# RA4M1 register map
Vendor: Renesas Electronics Corporation; Series: RA4; File version: 1.2
CPU: CM4 r0p1, little endian, MPU, FPU, VTOR, 4 interrupt priority bits
Registers are 8-bit, read-write, reset 0x0 unless marked. A register's access mark holds for its fields unless they carry their own. Offsets are from the block's base; [hi:lo] are bit positions; {n}, {i} and the like mark numbered series.

## GPT162 (part 1 of 2) — General PWM Timer 2 (16-bit)
Base 0x40078200
Same registers: GPT163 0x40078300, GPT164 0x40078400, GPT165 0x40078500, GPT166 0x40078600, GPT167 0x40078700
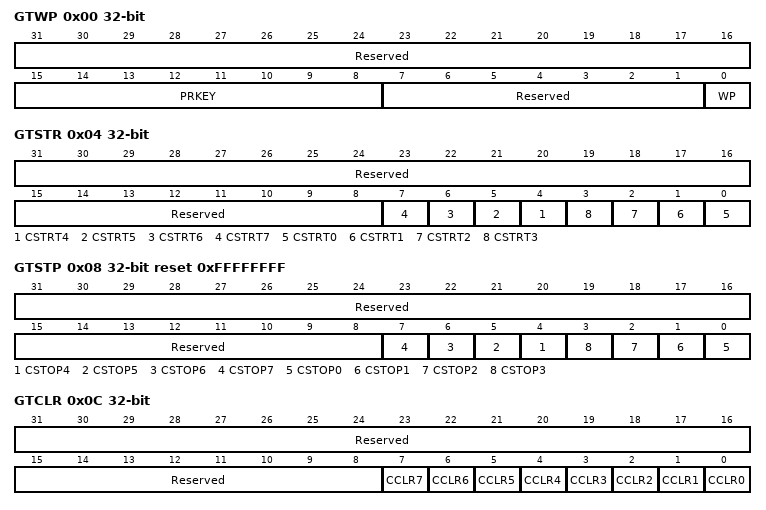
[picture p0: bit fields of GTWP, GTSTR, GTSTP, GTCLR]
0x00 GTWP 32-bit — General PWM Timer Write-Protection Register
  [31:16] Reserved — These bits are read as 0000000000000000. The write value should be 0000000000000000.
  [15:8] PRKEY wo — GTWP Key Code
    165=Written to these bits, the WP bits write is permitted; other=others (The WP bits write is not permitted.)
  [7:1] Reserved — These bits are read as 0000000. The write value should be 0000000.
  [0] WP — Register Write Disable
    0=Write to the register is enabled; 1=Write to the register is disabled
0x04 GTSTR 32-bit — General PWM Timer Software Start Register
  [31:8] Reserved — These bits are read as 000000000000000000000000. The write value should be 000000000000000000000000.
  [n] CSTRT{n} (n=4..7) — Channel {n} GTCNT Count Start Read data shows each channel's counter status (GTCR.CST bit). 0 means counter stop. 1 means counter running.
    0=No effect (write) / counter stop (read); 1=GPT{n+160}.GTCNT counter starts (write) / Counter running (read)
  [n] CSTRT{n} (n=0..3) — Channel {n} GTCNT Count Start Read data shows each channel's counter status (GTCR.CST bit). 0 means counter stop. 1 means counter running.
    0=No effect (write) / counter stop (read); 1=GPT{n+320}.GTCNT counter starts (write) / Counter running (read)
0x08 GTSTP 32-bit reset 0xFFFFFFFF — General PWM Timer Software Stop Register
  [31:8] Reserved — These bits are read as 111111111111111111111111. The write value should be 111111111111111111111111.
  [n] CSTOP{n} (n=4..7) — Channel {n} GTCNT Count Stop Read data shows each channel's counter status (GTCR.CST bit). 0 means counter runnning. 1 means counter stop.
    0=No effect (write) / counter running (read); 1=GPT{n+160}.GTCNT counter stops (write) / Counter stop (read)
  [n] CSTOP{n} (n=0..3) — Channel {n} GTCNT Count Stop Read data shows each channel's counter status (GTCR.CST bit). 0 means counter runnning. 1 means counter stop.
    0=No effect (write) / counter running (read); 1=GPT{n+320}.GTCNT counter stops (write) / Counter stop (read)
0x0C GTCLR 32-bit wo — General PWM Timer Software Clear Register
  [31:8] Reserved — The write value should be 000000000000000000000000.
  [n] CCLR{n} (n=4..7) — Channel {n} GTCNT Count Clear
    0=No effect; 1=GPT{n+160}.GTCNT counter clears
  [n] CCLR{n} (n=0..3) — Channel {n} GTCNT Count Clear
    0=No effect; 1=GPT{n+320}.GTCNT counter clears
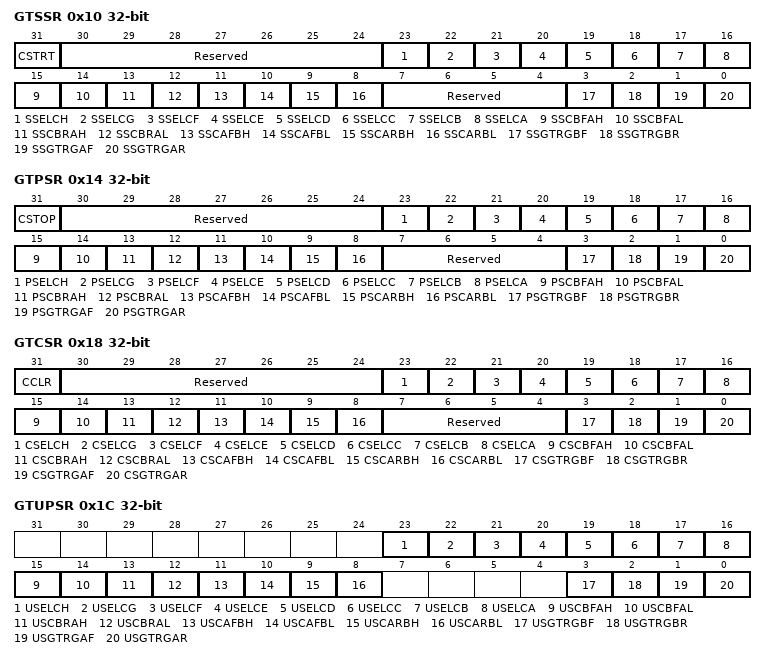
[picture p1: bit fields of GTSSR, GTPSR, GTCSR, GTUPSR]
0x10 GTSSR 32-bit — General PWM Timer Start Source Select Register
  [31] CSTRT — Software Source Counter Start Enable
    0=Counter start is disable by the GTSTR register; 1=Counter start is enable by the GTSTR register
  [30:24] Reserved — These bits are read as 0000000. The write value should be 0000000.
  [23] SSELCH — ELC_GPTH Event Source Counter Start Enable
    0=Counter start is disable at the ELC_GPTH input; 1=Counter start is enable at the ELC_GPTH input
  [22] SSELCG — ELC_GPTG Event Source Counter Start Enable
    0=Counter start is disable at the ELC_GPTG input; 1=Counter start is enable at the ELC_GPTG input
  [21] SSELCF — ELC_GPTF Event Source Counter Start Enable
    0=Counter start is disable at the ELC_GPTF input; 1=Counter start is enable at the ELC_GPTF input
  [20] SSELCE — ELC_GPTE Event Source Counter Start Enable
    0=Counter start is disable at the ELC_GPTE input; 1=Counter start is enable at the ELC_GPTE input
  [19] SSELCD — ELC_GPTD Event Source Counter Start Enable
    0=Counter start is disable at the ELC_GPTD input; 1=Counter start is enable at the ELC_GPTD input
  [18] SSELCC — ELC_GPTC Event Source Counter Start Enable
    0=Counter start is disable at the ELC_GPTC input; 1=Counter start is enable at the ELC_GPTC input
  [17] SSELCB — ELC_GPTB Event Source Counter Start Enable
    0=Counter start is disable at the ELC_GPTB input; 1=Counter start is enable at the ELC_GPTB input
  [16] SSELCA — ELC_GPTA Event Source Counter Start Enable
    0=Counter start is disable at the ELC_GPTA input; 1=Counter start is enable at the ELC_GPTA input
  [15] SSCBFAH — GTIOCB Pin Falling Input during GTIOCA Value High Source Counter Start Enable
    0=Counter start is disable at the falling edge of GTIOCB input when GTIOCA input is 1; 1=Counter start is enable at the falling edge of GTIOCB input when GTIOCA input is 1
  [14] SSCBFAL — GTIOCB Pin Falling Input during GTIOCA Value Low Source Counter Start Enable
    0=Counter start is disable at the falling edge of GTIOCB input when GTIOCA input is 0; 1=Counter start is enable at the falling edge of GTIOCB input when GTIOCA input is 0
  [13] SSCBRAH — GTIOCB Pin Rising Input during GTIOCA Value High Source Counter Start Enable
    0=Counter start is disable at the rising edge of GTIOCB input when GTIOCA input is 1; 1=Counter start is enable at the rising edge of GTIOCB input when GTIOCA input is 1
  [12] SSCBRAL — GTIOCB Pin Rising Input during GTIOCA Value Low Source Counter Start Enable
    0=Counter start is disable at the rising edge of GTIOCB input when GTIOCA input is 0; 1=Counter start is enable at the rising edge of GTIOCB input when GTIOCA input is 0
  [11] SSCAFBH — GTIOCA Pin Falling Input during GTIOCB Value High Source Counter Start Enable
    0=Counter start is disable at the falling edge of GTIOCA input when GTIOCB input is 1; 1=Counter start is enable at the falling edge of GTIOCA input when GTIOCB input is 1
  [10] SSCAFBL — GTIOCA Pin Falling Input during GTIOCB Value Low Source Counter Start Enable
    0=Counter start is disable at the falling edge of GTIOCA input when GTIOCB input is 0; 1=Counter start is enable at the falling edge of GTIOCA input when GTIOCB input is 0
  [9] SSCARBH — GTIOCA Pin Rising Input during GTIOCB Value High Source Counter Start Enable
    0=Counter start is disable at the rising edge of GTIOCA input when GTIOCB input is 1; 1=Counter start is enable at the rising edge of GTIOCA input when GTIOCB input is 1
  [8] SSCARBL — GTIOCA Pin Rising Input during GTIOCB Value Low Source Counter Start Enable
    0=Counter start is disable at the rising edge of GTIOCA input when GTIOCB input is 0; 1=Counter start is enable at the rising edge of GTIOCA input when GTIOCB input is 0
  [7:4] Reserved — These bits are read as 0000. The write value should be 0000.
  [3] SSGTRGBF — GTETRGB Pin Falling Input Source Counter Start Enable
    0=Counter start is disable at the falling edge of GTETRGB input; 1=Counter start is enable at the falling edge of GTETRGB input
  [2] SSGTRGBR — GTETRGB Pin Rising Input Source Counter Start Enable
    0=Counter start is disable at the rising edge of GTETRGB input; 1=Counter start is enable at the rising edge of GTETRGB input
  [1] SSGTRGAF — GTETRGA Pin Falling Input Source Counter Start Enable
    0=Counter start is disable at the falling edge of GTETRGA input; 1=Counter start is enable at the falling edge of GTETRGA input
  [0] SSGTRGAR — GTETRGA Pin Rising Input Source Counter Start Enable
    0=Counter start is disable at the rising edge of GTETRGA input; 1=Counter start is enable at the rising edge of GTETRGA input
0x14 GTPSR 32-bit — General PWM Timer Stop Source Select Register
  [31] CSTOP — Software Source Counter Stop Enable
    0=Counter stop is disable by the GTSTP register; 1=Counter stop is enable by the GTSTP register
  [30:24] Reserved — These bits are read as 0000000. The write value should be 0000000.
  [23] PSELCH — ELC_GPTH Event Source Counter Stop Enable
    0=Counter stop is disable at the ELC_GPTH input; 1=Counter stop is enable at the ELC_GPTH input
  [22] PSELCG — ELC_GPTG Event Source Counter Stop Enable
    0=Counter stop is disable at the ELC_GPTG input; 1=Counter stop is enable at the ELC_GPTG input
  [21] PSELCF — ELC_GPTF Event Source Counter Stop Enable
    0=Counter stop is disable at the ELC_GPTF input; 1=Counter stop is enable at the ELC_GPTF input
  [20] PSELCE — ELC_GPTE Event Source Counter Stop Enable
    0=Counter stop is disable at the ELC_GPTE input; 1=Counter stop is enable at the ELC_GPTE input
  [19] PSELCD — ELC_GPTD Event Source Counter Stop Enable
    0=Counter stop is disable at the ELC_GPTD input; 1=Counter stop is enable at the ELC_GPTD input
  [18] PSELCC — ELC_GPTC Event Source Counter Stop Enable
    0=Counter stop is disable at the ELC_GPTC input; 1=Counter stop is enable at the ELC_GPTC input
  [17] PSELCB — ELC_GPTB Event Source Counter Stop Enable
    0=Counter stop is disable at the ELC_GPTB input; 1=Counter stop is enable at the ELC_GPTB input
  [16] PSELCA — ELC_GPTA Event Source Counter Stop Enable
    0=Counter stop is disable at the ELC_GPTA input; 1=Counter stop is enable at the ELC_GPTA input
  [15] PSCBFAH — GTIOCB Pin Falling Input during GTIOCA Value High Source Counter Stop Enable
    0=Counter stop is disable at the falling edge of GTIOCB input when GTIOCA input is 1; 1=Counter stop is enable at the falling edge of GTIOCB input when GTIOCA input is 1
  [14] PSCBFAL — GTIOCB Pin Falling Input during GTIOCA Value Low Source Counter Stop Enable
    0=Counter stop is disable at the falling edge of GTIOCB input when GTIOCA input is 0; 1=Counter stop is enable at the falling edge of GTIOCB input when GTIOCA input is 0
  [13] PSCBRAH — GTIOCB Pin Rising Input during GTIOCA Value High Source Counter Stop Enable
    0=Counter stop is disable at the rising edge of GTIOCB input when GTIOCA input is 1; 1=Counter stop is enable at the rising edge of GTIOCB input when GTIOCA input is 1
  [12] PSCBRAL — GTIOCB Pin Rising Input during GTIOCA Value Low Source Counter Stop Enable
    0=Counter stop is disable at the rising edge of GTIOCB input when GTIOCA input is 0; 1=Counter stop is enable at the rising edge of GTIOCB input when GTIOCA input is 0
  [11] PSCAFBH — GTIOCA Pin Falling Input during GTIOCB Value High Source Counter Stop Enable
    0=Counter stop is disable at the falling edge of GTIOCA input when GTIOCB input is 1; 1=Counter stop is enable at the falling edge of GTIOCA input when GTIOCB input is 1
  [10] PSCAFBL — GTIOCA Pin Falling Input during GTIOCB Value Low Source Counter Stop Enable
    0=Counter stop is disable at the falling edge of GTIOCA input when GTIOCB input is 0; 1=Counter stop is enable at the falling edge of GTIOCA input when GTIOCB input is 0
  [9] PSCARBH — GTIOCA Pin Rising Input during GTIOCB Value High Source Counter Stop Enable
    0=Counter stop is disable at the rising edge of GTIOCA input when GTIOCB input is 1; 1=Counter stop is enable at the rising edge of GTIOCA input when GTIOCB input is 1
  [8] PSCARBL — GTIOCA Pin Rising Input during GTIOCB Value Low Source Counter Stop Enable
    0=Counter stop is disable at the rising edge of GTIOCA input when GTIOCB input is 0; 1=Counter stop is enable at the rising edge of GTIOCA input when GTIOCB input is 0
  [7:4] Reserved — These bits are read as 0000. The write value should be 0000.
  [3] PSGTRGBF — GTETRGB Pin Falling Input Source Counter Stop Enable
    0=Counter stop is disable at the falling edge of GTETRGB input; 1=Counter stop is enable at the falling edge of GTETRGB input
  [2] PSGTRGBR — GTETRGB Pin Rising Input Source Counter Stop Enable
    0=Counter stop is disable at the rising edge of GTETRGB input; 1=Counter stop is enable at the rising edge of GTETRGB input
  [1] PSGTRGAF — GTETRGA Pin Falling Input Source Counter Stop Enable
    0=Counter stop is disable at the falling edge of GTETRGA input; 1=Counter stop is enable at the falling edge of GTETRGA input
  [0] PSGTRGAR — GTETRGA Pin Rising Input Source Counter Stop Enable
    0=Counter stop is disable at the rising edge of GTETRGA input; 1=Counter stop is enable at the rising edge of GTETRGA input
0x18 GTCSR 32-bit — General PWM Timer Clear Source Select Register
  [31] CCLR — Software Source Counter Clear Enable
    0=Counter clear is disable by the GTCLR register; 1=Counter clear is enable by the GTCLR register
  [30:24] Reserved — These bits are read as 0000000. The write value should be 0000000.
  [23] CSELCH — ELC_GPTH Event Source Counter Clear Enable
    0=Counter clear is disable at the ELC_GPTH input; 1=Counter clear is enable at the ELC_GPTH input
  [22] CSELCG — ELC_GPTG Event Source Counter Clear Enable
    0=Counter clear is disable at the ELC_GPTG input; 1=Counter clear is enable at the ELC_GPTG input
  [21] CSELCF — ELC_GPTF Event Source Counter Clear Enable
    0=Counter clear is disable at the ELC_GPTF input; 1=Counter clear is enable at the ELC_GPTF input
  [20] CSELCE — ELC_GPTE Event Source Counter Clear Enable
    0=Counter clear is disable at the ELC_GPTE input; 1=Counter clear is enable at the ELC_GPTE input
  [19] CSELCD — ELC_GPTD Event Source Counter Clear Enable
    0=Counter clear is disable at the ELC_GPTD input; 1=Counter clear is enable at the ELC_GPTD input
  [18] CSELCC — ELC_GPTC Event Source Counter Clear Enable
    0=Counter clear is disable at the ELC_GPTC input; 1=Counter clear is enable at the ELC_GPTC input
  [17] CSELCB — ELC_GPTB Event Source Counter Clear Enable
    0=Counter clear is disable at the ELC_GPTB input; 1=Counter clear is enable at the ELC_GPTB input
  [16] CSELCA — ELC_GPTA Event Source Counter Clear Enable
    0=Counter clear is disable at the ELC_GPTA input; 1=Counter clear is enable at the ELC_GPTA input
  [15] CSCBFAH — GTIOCB Pin Falling Input during GTIOCA Value High Source Counter Clear Enable
    0=Counter clear is disable at the falling edge of GTIOCB input when GTIOCA input is 1; 1=Counter clear is enable at the falling edge of GTIOCB input when GTIOCA input is 1
  [14] CSCBFAL — GTIOCB Pin Falling Input during GTIOCA Value Low Source Counter Clear Enable
    0=Counter clear is disable at the falling edge of GTIOCB input when GTIOCA input is 0; 1=Counter clear is enable at the falling edge of GTIOCB input when GTIOCA input is 0
  [13] CSCBRAH — GTIOCB Pin Rising Input during GTIOCA Value High Source Counter Clear Enable
    0=Counter clear is disable at the rising edge of GTIOCB input when GTIOCA input is 1; 1=Counter clear is enable at the rising edge of GTIOCB input when GTIOCA input is 1
  [12] CSCBRAL — GTIOCB Pin Rising Input during GTIOCA Value Low Source Counter Clear Enable
    0=Counter clear is disable at the rising edge of GTIOCB input when GTIOCA input is 0; 1=Counter clear is enable at the rising edge of GTIOCB input when GTIOCA input is 0
  [11] CSCAFBH — GTIOCA Pin Falling Input during GTIOCB Value High Source Counter Clear Enable
    0=Counter clear is disable at the falling edge of GTIOCA input when GTIOCB input is 1; 1=Counter clear is enable at the falling edge of GTIOCA input when GTIOCB input is 1
  [10] CSCAFBL — GTIOCA Pin Falling Input during GTIOCB Value Low Source Counter Clear Enable
    0=Counter clear is disable at the falling edge of GTIOCA input when GTIOCB input is 0; 1=Counter clear is enable at the falling edge of GTIOCA input when GTIOCB input is 0
  [9] CSCARBH — GTIOCA Pin Rising Input during GTIOCB Value High Source Counter Clear Enable
    0=Counter clear is disable at the rising edge of GTIOCA input when GTIOCB input is 1; 1=Counter clear is enable at the rising edge of GTIOCA input when GTIOCB input is 1
  [8] CSCARBL — GTIOCA Pin Rising Input during GTIOCB Value Low Source Counter Clear Enable
    0=Counter clear is disable at the rising edge of GTIOCA input when GTIOCB input is 0; 1=Counter clear is enable at the rising edge of GTIOCA input when GTIOCB input is 0
  [7:4] Reserved — These bits are read as 0000. The write value should be 0000.
  [3] CSGTRGBF — GTETRGB Pin Falling Input Source Counter Clear Enable
    0=Counter clear is disable at the falling edge of GTETRGB input; 1=Counter clear is enable at the falling edge of GTETRGB input
  [2] CSGTRGBR — GTETRGB Pin Rising Input Source Counter Clear Enable
    0=Counter clear is disable at the rising edge of GTETRGB input; 1=Counter clear is enable at the rising edge of GTETRGB input
  [1] CSGTRGAF — GTETRGA Pin Falling Input Source Counter Clear Enable
    0=Counter clear is disable at the falling edge of GTETRGA input; 1=Counter clear is enable at the falling edge of GTETRGA input
  [0] CSGTRGAR — GTETRGA Pin Rising Input Source Counter Clear Enable
    0=Counter clear is disable at the rising edge of GTETRGA input; 1=Counter clear is enable at the rising edge of GTETRGA input
0x1C GTUPSR 32-bit — General PWM Timer Up Count Source Select Register
  [23] USELCH — ELC_GPTH Event Source Counter Count Up Enable
    0=Counter count up is disable at the ELC_GPTH input; 1=Counter count up is enable at the ELC_GPTH input
  [22] USELCG — ELC_GPTG Event Source Counter Count Up Enable
    0=Counter count up is disable at the ELC_GPTG input; 1=Counter count up is enable at the ELC_GPTG input
  [21] USELCF — ELC_GPTF Event Source Counter Count Up Enable
    0=Counter count up is disable at the ELC_GPTF input; 1=Counter count up is enable at the ELC_GPTF input
  [20] USELCE — ELC_GPTE Event Source Counter Count Up Enable
    0=Counter count up is disable at the ELC_GPTE input; 1=Counter count up is enable at the ELC_GPTE input
  [19] USELCD — ELC_GPTD Event Source Counter Count Up Enable
    0=Counter count up is disable at the ELC_GPTD input; 1=Counter count up is enable at the ELC_GPTD input
  [18] USELCC — ELC_GPTC Event Source Counter Count Up Enable
    0=Counter count up is disable at the ELC_GPTC input; 1=Counter count up is enable at the ELC_GPTC input
  [17] USELCB — ELC_GPTB Event Source Counter Count Up Enable
    0=Counter count up is disable at the ELC_GPTB input; 1=Counter count up is enable at the ELC_GPTB input
  [16] USELCA — ELC_GPTA Event Source Counter Count Up Enable
    0=Counter count up is disable at the ELC_GPTA input; 1=Counter count up is enable at the ELC_GPTA input
  [15] USCBFAH — GTIOCB Pin Falling Input during GTIOCA Value High Source Counter Count Up Enable
    0=Counter count up is disable at the falling edge of GTIOCB input when GTIOCA input is 1; 1=Counter count up is enable at the falling edge of GTIOCB input when GTIOCA input is 1
  [14] USCBFAL — GTIOCB Pin Falling Input during GTIOCA Value Low Source Counter Count Up Enable
    0=Counter count up is disable at the falling edge of GTIOCB input when GTIOCA input is 0; 1=Counter count up is enable at the falling edge of GTIOCB input when GTIOCA input is 0
  [13] USCBRAH — GTIOCB Pin Rising Input during GTIOCA Value High Source Counter Count Up Enable
    0=Counter count up is disable at the rising edge of GTIOCB input when GTIOCA input is 1; 1=Counter count up is enable at the rising edge of GTIOCB input when GTIOCA input is 1
  [12] USCBRAL — GTIOCB Pin Rising Input during GTIOCA Value Low Source Counter Count Up Enable
    0=Counter count up is disable at the rising edge of GTIOCB input when GTIOCA input is 0; 1=Counter count up is enable at the rising edge of GTIOCB input when GTIOCA input is 0
  [11] USCAFBH — GTIOCA Pin Falling Input during GTIOCB Value High Source Counter Count Up Enable
    0=Counter count up is disable at the falling edge of GTIOCA input when GTIOCB input is 1; 1=Counter count up is enable at the falling edge of GTIOCA input when GTIOCB input is 1
  [10] USCAFBL — GTIOCA Pin Falling Input during GTIOCB Value Low Source Counter Count Up Enable
    0=Counter count up is disable at the falling edge of GTIOCA input when GTIOCB input is 0; 1=Counter count up is enable at the falling edge of GTIOCA input when GTIOCB input is 0
  [9] USCARBH — GTIOCA Pin Rising Input during GTIOCB Value High Source Counter Count Up Enable
    0=Counter count up is disable at the rising edge of GTIOCA input when GTIOCB input is 1; 1=Counter count up is enable at the rising edge of GTIOCA input when GTIOCB input is 1
  [8] USCARBL — GTIOCA Pin Rising Input during GTIOCB Value Low Source Counter Count Up Enable
    0=Counter count up is disable at the rising edge of GTIOCA input when GTIOCB input is 0; 1=Counter count up is enable at the rising edge of GTIOCA input when GTIOCB input is 0
  [3] USGTRGBF — GTETRGB Pin Falling Input Source Counter Count Up Enable
    0=Counter count up is disable at the falling edge of GTETRGB input; 1=Counter count up is enable at the falling edge of GTETRGB input
  [2] USGTRGBR — GTETRGB Pin Rising Input Source Counter Count Up Enable
    0=Counter count up is disable at the rising edge of GTETRGB input; 1=Counter count up is enable at the rising edge of GTETRGB input
  [1] USGTRGAF — GTETRGA Pin Falling Input Source Counter Count Up Enable
    0=Counter count up is disable at the falling edge of GTETRGA input; 1=Counter count up is enable at the falling edge of GTETRGA input
  [0] USGTRGAR — GTETRGA Pin Rising Input Source Counter Count Up Enable
    0=Counter count up is disable at the rising edge of GTETRGA input; 1=Counter count up is enable at the rising edge of GTETRGA input
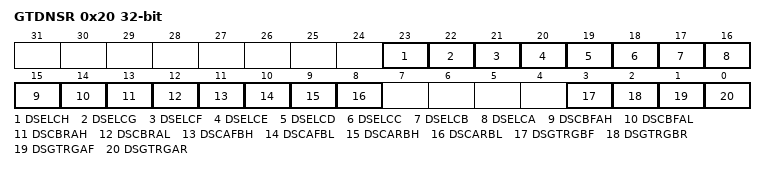
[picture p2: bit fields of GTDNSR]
0x20 GTDNSR 32-bit — General PWM Timer Down Count Source Select Register
  [23] DSELCH — ELC_GPTH Event Source Counter Count Down Enable
    0=Counter count down is disable at the ELC_GPTH input; 1=Counter count down is enable at the ELC_GPTH input
  [22] DSELCG — ELC_GPTG Event Source Counter Count Down Enable
    0=Counter count down is disable at the ELC_GPTG input; 1=Counter count down is enable at the ELC_GPTG input
  [21] DSELCF — ELC_GPTF Event Source Counter Count Down Enable
    0=Counter count down is disable at the ELC_GPTF input; 1=Counter count down is enable at the ELC_GPTF input
  [20] DSELCE — ELC_GPTE Event Source Counter Count Down Enable
    0=Counter count down is disable at the ELC_GPTE input; 1=Counter count down is enable at the ELC_GPTE input
  [19] DSELCD — ELC_GPTD Event Source Counter Count Down Enable
    0=Counter count down is disable at the ELC_GPTD input; 1=Counter count down is enable at the ELC_GPTD input
  [18] DSELCC — ELC_GPTC Event Source Counter Count Down Enable
    0=Counter count down is disable at the ELC_GPTC input; 1=Counter count down is enable at the ELC_GPTC input
  [17] DSELCB — ELC_GPTB Event Source Counter Count Down Enable
    0=Counter count down is disable at the ELC_GPTB input; 1=Counter count down is enable at the ELC_GPTB input
  [16] DSELCA — ELC_GPTA Event Source Counter Count Down Enable
    0=Counter count down is disable at the ELC_GPTA input; 1=Counter count down is enable at the ELC_GPTA input
  [15] DSCBFAH — GTIOCB Pin Falling Input during GTIOCA Value High Source Counter Count Down Enable
    0=Counter count down is disable at the falling edge of GTIOCB input when GTIOCA input is 1; 1=Counter count down is enable at the falling edge of GTIOCB input when GTIOCA input is 1
  [14] DSCBFAL — GTIOCB Pin Falling Input during GTIOCA Value Low Source Counter Count Down Enable
    0=Counter count down is disable at the falling edge of GTIOCB input when GTIOCA input is 0; 1=Counter count down is enable at the falling edge of GTIOCB input when GTIOCA input is 0
  [13] DSCBRAH — GTIOCB Pin Rising Input during GTIOCA Value High Source Counter Count Down Enable
    0=Counter count down is disable at the rising edge of GTIOCB input when GTIOCA input is 1; 1=Counter count down is enable at the rising edge of GTIOCB input when GTIOCA input is 1
  [12] DSCBRAL — GTIOCB Pin Rising Input during GTIOCA Value Low Source Counter Count Down Enable
    0=Counter count down is disable at the rising edge of GTIOCB input when GTIOCA input is 0; 1=Counter count down is enable at the rising edge of GTIOCB input when GTIOCA input is 0
  [11] DSCAFBH — GTIOCA Pin Falling Input during GTIOCB Value High Source Counter Count Down Enable
    0=Counter count down is disable at the falling edge of GTIOCA input when GTIOCB input is 1; 1=Counter count down is enable at the falling edge of GTIOCA input when GTIOCB input is 1
  [10] DSCAFBL — GTIOCA Pin Falling Input during GTIOCB Value Low Source Counter Count Down Enable
    0=Counter count down is disable at the falling edge of GTIOCA input when GTIOCB input is 0; 1=Counter count down is enable at the falling edge of GTIOCA input when GTIOCB input is 0
  [9] DSCARBH — GTIOCA Pin Rising Input during GTIOCB Value High Source Counter Count Down Enable
    0=Counter count down is disable at the rising edge of GTIOCA input when GTIOCB input is 1; 1=Counter count down is enable at the rising edge of GTIOCA input when GTIOCB input is 1
  [8] DSCARBL — GTIOCA Pin Rising Input during GTIOCB Value Low Source Counter Count Down Enable
    0=Counter count down is disable at the rising edge of GTIOCA input when GTIOCB input is 0; 1=Counter count down is enable at the rising edge of GTIOCA input when GTIOCB input is 0
  [3] DSGTRGBF — GTETRGB Pin Falling Input Source Counter Count Down Enable
    0=Counter count down is disable at the falling edge of GTETRGB input; 1=Counter count down is enable at the falling edge of GTETRGB input
  [2] DSGTRGBR — GTETRGB Pin Rising Input Source Counter Count Down Enable
    0=Counter count down is disable at the rising edge of GTETRGB input; 1=Counter count down is enable at the rising edge of GTETRGB input
  [1] DSGTRGAF — GTETRGA Pin Falling Input Source Counter Count Down Enable
    0=Counter count down is disable at the falling edge of GTETRGA input; 1=Counter count down is enable at the falling edge of GTETRGA input
  [0] DSGTRGAR — GTETRGA Pin Rising Input Source Counter Count Down Enable
    0=Counter count down is disable at the rising edge of GTETRGA input; 1=Counter count down is enable at the rising edge of GTETRGA input
